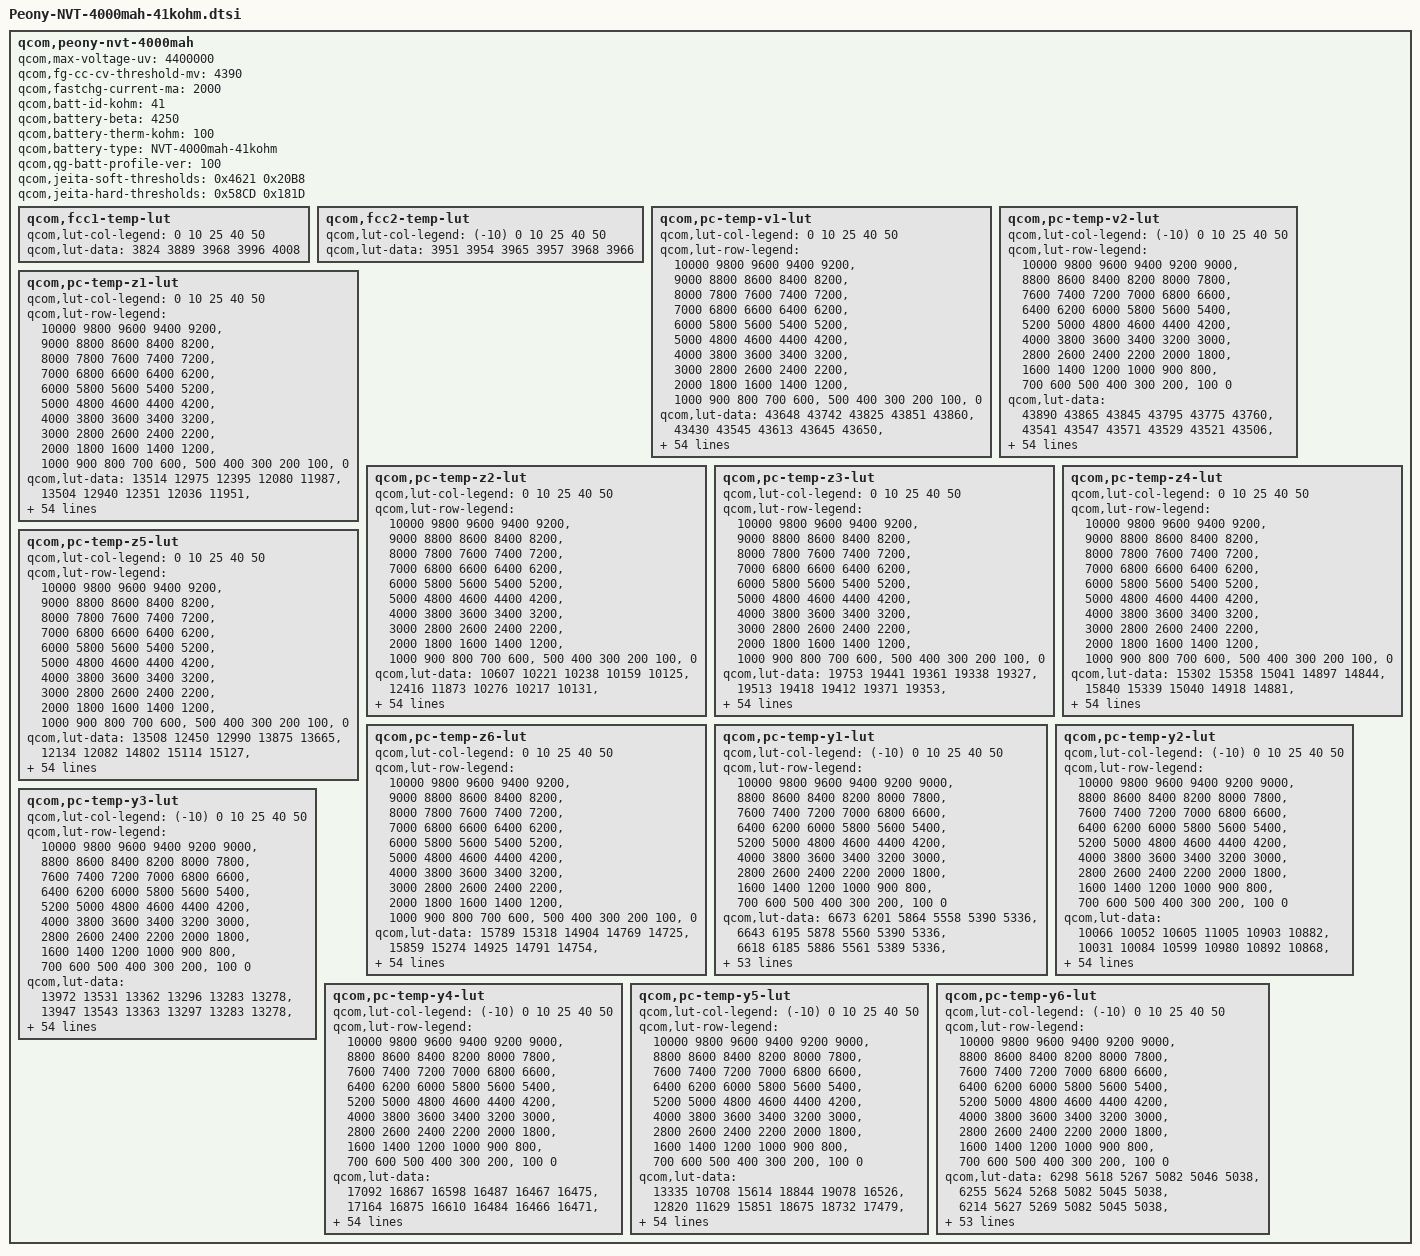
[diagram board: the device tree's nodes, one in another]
/* Copyright (c) 2018, The Linux Foundation. All rights reserved.
 * Copyright (C) 2021 XiaoMi, Inc.
 *
 * This program is free software; you can redistribute it and/or modify
 * it under the terms of the GNU General Public License version 2 and
 * only version 2 as published by the Free Software Foundation.
 *
 * This program is distributed in the hope that it will be useful,
 * but WITHOUT ANY WARRANTY; without even the implied warranty of
 * MERCHANTABILITY or FITNESS FOR A PARTICULAR PURPOSE.  See the
 * GNU General Public License for more details.
 */

qcom,peony-nvt-4000mah {
	/* Peony-NVT-4000mah-41kohm_Master_2018.12.27 */
	qcom,max-voltage-uv = <4400000>;
	qcom,fg-cc-cv-threshold-mv = <4390>;
	qcom,fastchg-current-ma = <2000>;
	qcom,batt-id-kohm = <41>;
	qcom,battery-beta = <4250>;
	qcom,battery-therm-kohm = <100>;
	qcom,battery-type =
		"NVT-4000mah-41kohm";
	qcom,qg-batt-profile-ver = <100>;

/*	qcom,jeita-fcc-ranges = <0   50   400000
				 51  100  1200000
				 101 150  1950000
				 151 450  2000000
				 451 550  1000000
				 551 600  0>;
	qcom,jeita-fv-ranges =  <0   50   4400000
				 51  100  4400000
				 101 150  4400000
				 151 450  4400000
				 451 550  4100000
				 551 600  4100000>;*/

	/* COOL = 15 DegC, WARM = 45 DegC */
	qcom,jeita-soft-thresholds = <0x4621 0x20B8>;
	/* COLD = 0 DegC, HOT = 55 DegC */
	qcom,jeita-hard-thresholds = <0x58CD 0x181D>;

	qcom,fcc1-temp-lut {
		qcom,lut-col-legend = <0 10 25 40 50>;
		qcom,lut-data = <3824 3889 3968 3996 4008>;
	};

	qcom,fcc2-temp-lut {
		qcom,lut-col-legend = <(-10) 0 10 25 40 50>;
		qcom,lut-data = <3951 3954 3965 3957 3968 3966>;
	};

	qcom,pc-temp-v1-lut {
		qcom,lut-col-legend = <0 10 25 40 50>;
		qcom,lut-row-legend = <10000 9800 9600 9400 9200>,
			<9000 8800 8600 8400 8200>,
			<8000 7800 7600 7400 7200>,
			<7000 6800 6600 6400 6200>,
			<6000 5800 5600 5400 5200>,
			<5000 4800 4600 4400 4200>,
			<4000 3800 3600 3400 3200>,
			<3000 2800 2600 2400 2200>,
			<2000 1800 1600 1400 1200>,
			<1000 900 800 700 600>,
			<500 400 300 200 100>,
			<0>;
		qcom,lut-data = <43648 43742 43825 43851 43860>,
			<43430 43545 43613 43645 43650>,
			<43175 43313 43394 43426 43434>,
			<42922 43056 43166 43204 43214>,
			<42688 42810 42932 42977 42989>,
			<42460 42577 42699 42747 42761>,
			<42234 42350 42467 42516 42529>,
			<42013 42126 42237 42285 42295>,
			<41796 41906 42012 42056 42067>,
			<41585 41689 41791 41828 41844>,
			<41380 41472 41571 41603 41623>,
			<41186 41262 41349 41380 41401>,
			<41012 41070 41133 41162 41181>,
			<40836 40898 40934 40956 40970>,
			<40617 40714 40743 40759 40764>,
			<40348 40482 40548 40565 40566>,
			<40111 40236 40338 40365 40374>,
			<39947 40044 40138 40169 40189>,
			<39809 39898 39972 39994 40015>,
			<39673 39758 39828 39844 39858>,
			<39544 39597 39653 39677 39688>,
			<39409 39426 39397 39446 39462>,
			<39245 39238 39142 39197 39214>,
			<39056 38997 38974 39015 39028>,
			<38882 38783 38845 38876 38890>,
			<38721 38677 38734 38755 38768>,
			<38581 38610 38637 38646 38650>,
			<38495 38547 38550 38547 38541>,
			<38436 38480 38466 38454 38444>,
			<38386 38416 38387 38364 38354>,
			<38338 38358 38315 38283 38275>,
			<38293 38304 38247 38210 38203>,
			<38252 38254 38185 38145 38138>,
			<38217 38208 38132 38085 38074>,
			<38184 38165 38086 38033 38015>,
			<38153 38126 38041 37981 37954>,
			<38125 38091 38000 37929 37893>,
			<38089 38051 37957 37873 37829>,
			<38031 37986 37893 37802 37750>,
			<37953 37896 37801 37710 37649>,
			<37859 37794 37698 37607 37540>,
			<37741 37678 37585 37497 37427>,
			<37605 37545 37457 37371 37300>,
			<37447 37386 37300 37212 37133>,
			<37307 37241 37157 37077 37009>,
			<37213 37149 37067 36988 36931>,
			<37188 37124 37040 36961 36907>,
			<37171 37108 37021 36944 36887>,
			<37150 37086 37005 36923 36864>,
			<37094 37035 36951 36858 36787>,
			<36870 36802 36698 36579 36478>,
			<36422 36361 36254 36140 36040>,
			<35849 35792 35681 35568 35464>,
			<35071 35015 34903 34790 34680>,
			<33834 33796 33683 33582 33461>,
			<30000 30000 30000 30000 30000>;
	};

	qcom,pc-temp-v2-lut {
		qcom,lut-col-legend = <(-10) 0 10 25 40 50>;
		qcom,lut-row-legend = <10000 9800 9600 9400 9200 9000>,
			<8800 8600 8400 8200 8000 7800>,
			<7600 7400 7200 7000 6800 6600>,
			<6400 6200 6000 5800 5600 5400>,
			<5200 5000 4800 4600 4400 4200>,
			<4000 3800 3600 3400 3200 3000>,
			<2800 2600 2400 2200 2000 1800>,
			<1600 1400 1200 1000 900 800>,
			<700 600 500 400 300 200>,
			<100 0>;
		qcom,lut-data = <43890 43865 43845 43795 43775 43760>,
			<43541 43547 43571 43529 43521 43506>,
			<43216 43250 43306 43271 43272 43258>,
			<42916 42977 43051 43024 43031 43019>,
			<42635 42727 42808 42786 42797 42788>,
			<42380 42484 42568 42552 42565 42559>,
			<42163 42238 42331 42319 42333 42327>,
			<41961 41994 42097 42087 42102 42096>,
			<41732 41755 41867 41859 41874 41868>,
			<41454 41516 41641 41635 41648 41642>,
			<41216 41296 41420 41413 41425 41419>,
			<41085 41112 41209 41197 41207 41201>,
			<40985 40944 41006 40985 40992 40986>,
			<40811 40760 40803 40780 40787 40780>,
			<40452 40558 40600 40579 40589 40580>,
			<40067 40336 40398 40383 40396 40388>,
			<39783 40060 40198 40184 40202 40199>,
			<39536 39750 39999 39987 40013 40016>,
			<39332 39509 39789 39805 39835 39841>,
			<39169 39336 39560 39644 39677 39679>,
			<39018 39178 39337 39476 39508 39507>,
			<38856 39005 39132 39260 39287 39287>,
			<38692 38830 38941 39014 39038 39041>,
			<38546 38675 38777 38818 38842 38847>,
			<38416 38544 38638 38672 38693 38698>,
			<38304 38422 38514 38549 38566 38571>,
			<38220 38297 38402 38436 38452 38455>,
			<38153 38173 38299 38336 38350 38352>,
			<38092 38083 38204 38244 38258 38259>,
			<38034 38026 38113 38157 38174 38174>,
			<37980 37980 38033 38079 38098 38097>,
			<37929 37935 37963 38007 38028 38026>,
			<37882 37894 37902 37941 37965 37961>,
			<37836 37855 37850 37878 37897 37890>,
			<37791 37817 37810 37821 37823 37809>,
			<37746 37779 37771 37764 37743 37720>,
			<37695 37736 37728 37698 37651 37617>,
			<37639 37689 37684 37623 37548 37499>,
			<37574 37631 37630 37546 37454 37397>,
			<37497 37560 37557 37469 37376 37316>,
			<37409 37475 37469 37387 37298 37237>,
			<37314 37373 37365 37287 37202 37140>,
			<37207 37248 37238 37168 37089 37029>,
			<37117 37109 37095 37042 36967 36909>,
			<37040 36973 36964 36929 36864 36808>,
			<36963 36894 36895 36874 36815 36762>,
			<36921 36867 36870 36857 36804 36750>,
			<36872 36839 36841 36840 36789 36734>,
			<36790 36798 36804 36805 36754 36698>,
			<36635 36702 36698 36715 36642 36567>,
			<36321 36445 36414 36411 36306 36202>,
			<35843 35979 35918 35919 35809 35696>,
			<35193 35342 35276 35289 35165 35044>,
			<34312 34447 34395 34448 34302 34179>,
			<33008 33113 33150 33163 33003 32856>,
			<27916 28151 28492 28147 28387 28206>;
	};

	qcom,pc-temp-z1-lut {
		qcom,lut-col-legend = <0 10 25 40 50>;
		qcom,lut-row-legend = <10000 9800 9600 9400 9200>,
			<9000 8800 8600 8400 8200>,
			<8000 7800 7600 7400 7200>,
			<7000 6800 6600 6400 6200>,
			<6000 5800 5600 5400 5200>,
			<5000 4800 4600 4400 4200>,
			<4000 3800 3600 3400 3200>,
			<3000 2800 2600 2400 2200>,
			<2000 1800 1600 1400 1200>,
			<1000 900 800 700 600>,
			<500 400 300 200 100>,
			<0>;
		qcom,lut-data = <13514 12975 12395 12080 11987>,
			<13504 12940 12351 12036 11951>,
			<13474 12903 12318 12016 11932>,
			<13451 12863 12299 12004 11922>,
			<13435 12837 12284 11995 11917>,
			<13421 12818 12269 11988 11914>,
			<13405 12804 12253 11982 11911>,
			<13383 12797 12240 11978 11909>,
			<13365 12787 12233 11977 11909>,
			<13355 12777 12228 11977 11911>,
			<13348 12756 12226 11977 11912>,
			<13338 12735 12225 11977 11912>,
			<13304 12727 12225 11977 11912>,
			<13264 12724 12223 11977 11912>,
			<13242 12721 12220 11977 11913>,
			<13225 12712 12218 11977 11914>,
			<13216 12700 12216 11977 11915>,
			<13216 12696 12214 11977 11915>,
			<13219 12697 12215 11977 11916>,
			<13220 12698 12220 11978 11918>,
			<13227 12701 12224 11980 11919>,
			<13235 12709 12227 11981 11919>,
			<13239 12712 12230 11983 11920>,
			<13247 12711 12233 11984 11921>,
			<13249 12709 12237 11986 11923>,
			<13243 12712 12241 11988 11926>,
			<13235 12720 12245 11991 11929>,
			<13236 12727 12250 11995 11932>,
			<13246 12734 12256 11999 11936>,
			<13258 12742 12264 12004 11939>,
			<13269 12746 12272 12009 11942>,
			<13282 12749 12280 12013 11946>,
			<13291 12751 12287 12018 11951>,
			<13292 12759 12292 12022 11955>,
			<13293 12769 12296 12027 11958>,
			<13302 12773 12300 12031 11962>,
			<13323 12773 12308 12036 11965>,
			<13334 12774 12317 12041 11969>,
			<13330 12783 12324 12045 11972>,
			<13325 12801 12330 12049 11976>,
			<13326 12809 12336 12053 11979>,
			<13339 12807 12345 12058 11982>,
			<13360 12807 12353 12062 11985>,
			<13402 12816 12356 12067 11987>,
			<13382 12824 12368 12073 11991>,
			<13373 12837 12368 12075 11992>,
			<13391 12852 12371 12074 11993>,
			<13366 12828 12375 12076 11993>,
			<13342 12811 12376 12079 11995>,
			<13389 12820 12377 12083 12000>,
			<13405 12840 12388 12091 12006>,
			<13367 12859 12401 12101 12013>,
			<13394 12893 12413 12110 12022>,
			<13459 12934 12445 12125 12038>,
			<13459 12934 12445 12125 12038>,
			<13459 12934 12445 12125 12038>;
	};

	qcom,pc-temp-z2-lut {
		qcom,lut-col-legend = <0 10 25 40 50>;
		qcom,lut-row-legend = <10000 9800 9600 9400 9200>,
			<9000 8800 8600 8400 8200>,
			<8000 7800 7600 7400 7200>,
			<7000 6800 6600 6400 6200>,
			<6000 5800 5600 5400 5200>,
			<5000 4800 4600 4400 4200>,
			<4000 3800 3600 3400 3200>,
			<3000 2800 2600 2400 2200>,
			<2000 1800 1600 1400 1200>,
			<1000 900 800 700 600>,
			<500 400 300 200 100>,
			<0>;
		qcom,lut-data = <10607 10221 10238 10159 10125>,
			<12416 11873 10276 10217 10131>,
			<10926 11524 10299 10241 10190>,
			<10092 10567 10303 10271 10230>,
			<10072 10184 10304 10319 10297>,
			<10058 10166 10301 10346 10343>,
			<10043 10155 10282 10323 10342>,
			<10026 10144 10263 10284 10334>,
			<10016 10134 10340 10263 10310>,
			<10017 10128 10540 10248 10195>,
			<10021 10124 10601 10238 10099>,
			<10029 10122 10425 10236 10084>,
			<10079 10151 10252 10235 10079>,
			<10135 10276 10325 10220 10087>,
			<10129 10356 10539 10169 10117>,
			<10069 10309 10637 10134 10141>,
			<10029 10233 10653 10125 10136>,
			<10049 10223 10661 10122 10123>,
			<10092 10244 10593 10127 10122>,
			<10123 10269 10394 10141 10143>,
			<10146 10289 10319 10166 10177>,
			<10165 10309 10381 10285 10263>,
			<10180 10317 10442 10446 10388>,
			<10193 10320 10422 10450 10412>,
			<10202 10321 10342 10304 10338>,
			<10209 10319 10307 10208 10278>,
			<10214 10310 10346 10259 10380>,
			<10216 10306 10392 10332 10561>,
			<10216 10314 10397 10348 10582>,
			<10217 10323 10394 10346 10417>,
			<10221 10326 10391 10336 10248>,
			<10229 10324 10380 10311 10149>,
			<10237 10324 10367 10279 10075>,
			<10246 10329 10368 10256 10064>,
			<10257 10338 10377 10236 10088>,
			<10268 10347 10388 10227 10123>,
			<10279 10356 10402 10264 10173>,
			<10290 10367 10422 10327 10233>,
			<10301 10383 10452 10352 10275>,
			<10312 10402 10502 10370 10311>,
			<10323 10413 10528 10375 10327>,
			<10335 10417 10526 10366 10315>,
			<10349 10423 10524 10354 10300>,
			<10376 10437 10524 10340 10368>,
			<10595 10559 10560 10348 10342>,
			<10636 10601 10546 10374 10268>,
			<10652 10600 10538 10381 10293>,
			<10652 10639 10532 10357 10285>,
			<10651 10656 10539 10407 10333>,
			<10650 10677 10588 10470 10433>,
			<10649 10721 10678 10351 10199>,
			<10507 10710 10539 10205 10054>,
			<10381 10609 10501 10155 10014>,
			<10163 10526 10449 10095 9962>,
			<10163 10526 10449 10095 9962>,
			<10163 10526 10449 10095 9962>;
	};

	qcom,pc-temp-z3-lut {
		qcom,lut-col-legend = <0 10 25 40 50>;
		qcom,lut-row-legend = <10000 9800 9600 9400 9200>,
			<9000 8800 8600 8400 8200>,
			<8000 7800 7600 7400 7200>,
			<7000 6800 6600 6400 6200>,
			<6000 5800 5600 5400 5200>,
			<5000 4800 4600 4400 4200>,
			<4000 3800 3600 3400 3200>,
			<3000 2800 2600 2400 2200>,
			<2000 1800 1600 1400 1200>,
			<1000 900 800 700 600>,
			<500 400 300 200 100>,
			<0>;
		qcom,lut-data = <19753 19441 19361 19338 19327>,
			<19513 19418 19412 19371 19353>,
			<19674 19465 19447 19391 19373>,
			<19769 19573 19463 19403 19388>,
			<19772 19615 19474 19412 19398>,
			<19774 19614 19477 19417 19406>,
			<19776 19611 19477 19417 19413>,
			<19778 19606 19477 19418 19418>,
			<19779 19597 19479 19417 19418>,
			<19770 19590 19486 19414 19407>,
			<19747 19585 19485 19411 19396>,
			<19737 19582 19467 19408 19393>,
			<19743 19579 19449 19406 19391>,
			<19749 19570 19447 19401 19389>,
			<19748 19563 19449 19390 19386>,
			<19733 19559 19450 19384 19382>,
			<19713 19552 19450 19383 19378>,
			<19680 19544 19449 19383 19372>,
			<19641 19529 19442 19382 19366>,
			<19628 19517 19424 19375 19360>,
			<19625 19523 19417 19370 19356>,
			<19624 19536 19429 19375 19359>,
			<19637 19545 19443 19382 19366>,
			<19674 19549 19438 19380 19365>,
			<19693 19552 19419 19361 19349>,
			<19693 19549 19411 19349 19336>,
			<19692 19540 19412 19357 19362>,
			<19690 19534 19413 19374 19410>,
			<19680 19532 19418 19389 19421>,
			<19668 19531 19432 19406 19415>,
			<19659 19531 19441 19415 19407>,
			<19651 19531 19446 19412 19398>,
			<19644 19532 19449 19406 19387>,
			<19638 19531 19447 19399 19377>,
			<19632 19530 19440 19390 19369>,
			<19625 19528 19433 19382 19363>,
			<19618 19523 19426 19377 19357>,
			<19612 19518 19419 19373 19353>,
			<19609 19515 19417 19370 19352>,
			<19606 19513 19416 19367 19353>,
			<19601 19509 19414 19365 19355>,
			<19594 19504 19412 19364 19356>,
			<19586 19497 19408 19364 19360>,
			<19576 19488 19401 19365 19371>,
			<19507 19459 19393 19362 19367>,
			<19492 19445 19379 19353 19353>,
			<19456 19440 19379 19347 19340>,
			<19387 19420 19378 19341 19335>,
			<19344 19418 19363 19335 19330>,
			<19340 19414 19357 19333 19317>,
			<19348 19404 19342 19355 19364>,
			<19350 19391 19375 19368 19363>,
			<19350 19356 19377 19368 19365>,
			<19346 19355 19356 19369 19368>,
			<19346 19355 19356 19369 19368>,
			<19346 19355 19356 19369 19368>;
	};

	qcom,pc-temp-z4-lut {
		qcom,lut-col-legend = <0 10 25 40 50>;
		qcom,lut-row-legend = <10000 9800 9600 9400 9200>,
			<9000 8800 8600 8400 8200>,
			<8000 7800 7600 7400 7200>,
			<7000 6800 6600 6400 6200>,
			<6000 5800 5600 5400 5200>,
			<5000 4800 4600 4400 4200>,
			<4000 3800 3600 3400 3200>,
			<3000 2800 2600 2400 2200>,
			<2000 1800 1600 1400 1200>,
			<1000 900 800 700 600>,
			<500 400 300 200 100>,
			<0>;
		qcom,lut-data = <15302 15358 15041 14897 14844>,
			<15840 15339 15040 14918 14881>,
			<15687 15281 15034 14916 14882>,
			<15524 15176 15004 14908 14880>,
			<15395 15086 14941 14876 14855>,
			<15274 15013 14892 14843 14823>,
			<15178 14951 14858 14819 14799>,
			<15099 14905 14826 14798 14777>,
			<15037 14868 14786 14777 14761>,
			<14997 14838 14744 14755 14750>,
			<14967 14815 14726 14740 14741>,
			<14930 14794 14729 14731 14733>,
			<14859 14769 14734 14724 14727>,
			<14796 14735 14724 14719 14720>,
			<14791 14718 14702 14714 14712>,
			<14810 14732 14689 14710 14706>,
			<14823 14754 14683 14704 14702>,
			<14822 14756 14678 14698 14699>,
			<14819 14740 14675 14692 14694>,
			<14814 14726 14674 14683 14688>,
			<14795 14726 14683 14678 14684>,
			<14777 14728 14740 14717 14716>,
			<14777 14736 14807 14785 14782>,
			<14782 14805 14835 14820 14816>,
			<14788 14874 14853 14843 14834>,
			<14816 14875 14859 14852 14843>,
			<14849 14855 14845 14834 14807>,
			<14854 14834 14823 14798 14738>,
			<14842 14816 14799 14767 14713>,
			<14828 14799 14770 14734 14707>,
			<14816 14782 14746 14712 14702>,
			<14805 14766 14727 14702 14698>,
			<14794 14752 14713 14695 14694>,
			<14782 14741 14708 14692 14692>,
			<14771 14733 14705 14691 14689>,
			<14762 14727 14703 14691 14688>,
			<14753 14723 14702 14691 14688>,
			<14747 14721 14702 14692 14690>,
			<14744 14724 14704 14696 14694>,
			<14742 14730 14714 14709 14708>,
			<14743 14732 14719 14718 14717>,
			<14746 14729 14714 14712 14709>,
			<14746 14727 14709 14706 14699>,
			<14741 14724 14711 14707 14699>,
			<14727 14707 14697 14696 14688>,
			<14723 14696 14689 14683 14674>,
			<14754 14693 14676 14678 14674>,
			<14820 14702 14665 14666 14661>,
			<14859 14694 14665 14649 14641>,
			<14859 14696 14670 14647 14647>,
			<14857 14720 14713 14666 14654>,
			<14876 14746 14687 14664 14665>,
			<14886 14791 14690 14670 14668>,
			<14906 14799 14717 14672 14668>,
			<14906 14799 14717 14672 14668>,
			<14906 14799 14717 14672 14668>;
	};

	qcom,pc-temp-z5-lut {
		qcom,lut-col-legend = <0 10 25 40 50>;
		qcom,lut-row-legend = <10000 9800 9600 9400 9200>,
			<9000 8800 8600 8400 8200>,
			<8000 7800 7600 7400 7200>,
			<7000 6800 6600 6400 6200>,
			<6000 5800 5600 5400 5200>,
			<5000 4800 4600 4400 4200>,
			<4000 3800 3600 3400 3200>,
			<3000 2800 2600 2400 2200>,
			<2000 1800 1600 1400 1200>,
			<1000 900 800 700 600>,
			<500 400 300 200 100>,
			<0>;
		qcom,lut-data = <13508 12450 12990 13875 13665>,
			<12134 12082 14802 15114 15127>,
			<13430 13007 16165 16443 16555>,
			<14441 15315 17013 17264 17696>,
			<14784 16710 17654 17793 18467>,
			<15038 17272 18201 18203 19260>,
			<15420 17657 18654 18527 20606>,
			<16041 17972 19130 18837 22088>,
			<16525 18325 20492 19322 22365>,
			<16636 18777 22908 20079 21588>,
			<16690 19533 23824 20837 20963>,
			<16837 20416 22825 21660 21231>,
			<18284 21474 21745 22383 21945>,
			<20205 23672 22429 22362 22739>,
			<21081 24858 24623 21561 23886>,
			<21639 24581 26179 21034 24612>,
			<21885 24177 27482 21798 24591>,
			<20700 23745 28649 23372 24522>,
			<18572 23278 28544 24840 24599>,
			<17991 23049 27140 26382 25375>,
			<18780 27323 27551 27621 26144>,
			<20351 37012 35040 28666 26532>,
			<27003 40569 42650 29518 26857>,
			<42245 40041 39597 28313 26080>,
			<49655 38984 27894 21208 20052>,
			<48549 36140 21350 16543 15466>,
			<46279 30074 19821 16722 18205>,
			<43242 26497 19028 17212 23588>,
			<38107 25549 19384 18379 25838>,
			<33658 25020 21180 22012 26745>,
			<31349 25165 23484 25582 27129>,
			<29652 26331 27374 28133 26690>,
			<28820 27862 31462 30111 25926>,
			<28412 29990 33409 30572 25820>,
			<28154 32309 34715 30684 26253>,
			<27956 33120 35172 30723 26561>,
			<27746 33165 34154 30556 26491>,
			<27653 33078 32428 30161 26290>,
			<28454 32946 31170 29323 25823>,
			<29670 32549 30110 26862 24421>,
			<29659 31867 28893 24423 23410>,
			<27838 29746 27132 22584 23255>,
			<27006 27620 25190 21583 23200>,
			<27092 25974 22997 21851 27267>,
			<24674 26399 23724 21719 26850>,
			<23176 25084 21655 20076 21643>,
			<19121 23922 22538 19129 18313>,
			<14576 19737 23560 18830 18574>,
			<12781 19878 20139 20281 21398>,
			<12768 19724 19165 20181 17768>,
			<13023 17694 15134 19809 26177>,
			<12778 15603 18346 20365 20774>,
			<12584 13515 18358 18698 19185>,
			<12247 13223 14735 17630 17978>,
			<12247 13223 14735 17630 17978>,
			<12247 13223 14735 17630 17978>;
	};

	qcom,pc-temp-z6-lut {
		qcom,lut-col-legend = <0 10 25 40 50>;
		qcom,lut-row-legend = <10000 9800 9600 9400 9200>,
			<9000 8800 8600 8400 8200>,
			<8000 7800 7600 7400 7200>,
			<7000 6800 6600 6400 6200>,
			<6000 5800 5600 5400 5200>,
			<5000 4800 4600 4400 4200>,
			<4000 3800 3600 3400 3200>,
			<3000 2800 2600 2400 2200>,
			<2000 1800 1600 1400 1200>,
			<1000 900 800 700 600>,
			<500 400 300 200 100>,
			<0>;
		qcom,lut-data = <15789 15318 14904 14769 14725>,
			<15859 15274 14925 14791 14754>,
			<15811 15252 14933 14796 14760>,
			<15756 15237 14923 14794 14761>,
			<15683 15215 14898 14785 14755>,
			<15594 15172 14876 14774 14748>,
			<15529 15125 14859 14764 14742>,
			<15482 15091 14842 14754 14736>,
			<15441 15062 14827 14744 14728>,
			<15404 15039 14812 14734 14717>,
			<15372 15022 14801 14725 14708>,
			<15339 15007 14792 14720 14703>,
			<15300 14988 14785 14715 14699>,
			<15265 14963 14777 14709 14694>,
			<15246 14950 14769 14702 14689>,
			<15234 14951 14764 14695 14684>,
			<15223 14952 14761 14692 14679>,
			<15206 14950 14758 14690 14675>,
			<15188 14936 14752 14685 14669>,
			<15177 14924 14744 14678 14663>,
			<15170 14926 14742 14674 14659>,
			<15166 14935 14775 14695 14677>,
			<15172 14948 14812 14729 14710>,
			<15194 14982 14817 14737 14719>,
			<15214 15013 14818 14739 14719>,
			<15230 15012 14818 14739 14719>,
			<15243 15001 14814 14736 14717>,
			<15244 14990 14806 14730 14714>,
			<15236 14983 14801 14726 14711>,
			<15226 14977 14796 14722 14706>,
			<15219 14971 14792 14718 14700>,
			<15212 14966 14789 14713 14694>,
			<15205 14962 14785 14708 14687>,
			<15200 14959 14782 14703 14681>,
			<15195 14957 14778 14698 14676>,
			<15190 14956 14775 14694 14672>,
			<15186 14954 14772 14691 14670>,
			<15185 14953 14770 14689 14668>,
			<15187 14956 14771 14690 14668>,
			<15190 14961 14776 14694 14675>,
			<15194 14963 14778 14698 14679>,
			<15197 14963 14776 14695 14678>,
			<15200 14963 14774 14693 14676>,
			<15202 14962 14773 14695 14681>,
			<15178 14949 14766 14689 14675>,
			<15168 14941 14756 14679 14662>,
			<15164 14936 14751 14674 14656>,
			<15158 14931 14746 14666 14647>,
			<15155 14928 14739 14656 14637>,
			<15155 14930 14739 14654 14632>,
			<15166 14941 14753 14676 14662>,
			<15185 14951 14762 14685 14669>,
			<15201 14961 14769 14690 14674>,
			<15228 14977 14775 14695 14680>,
			<15228 14977 14775 14695 14680>,
			<15228 14977 14775 14695 14680>;
	};

	qcom,pc-temp-y1-lut {
		qcom,lut-col-legend = <(-10) 0 10 25 40 50>;
		qcom,lut-row-legend = <10000 9800 9600 9400 9200 9000>,
			<8800 8600 8400 8200 8000 7800>,
			<7600 7400 7200 7000 6800 6600>,
			<6400 6200 6000 5800 5600 5400>,
			<5200 5000 4800 4600 4400 4200>,
			<4000 3800 3600 3400 3200 3000>,
			<2800 2600 2400 2200 2000 1800>,
			<1600 1400 1200 1000 900 800>,
			<700 600 500 400 300 200>,
			<100 0>;
		qcom,lut-data = <6673 6201 5864 5558 5390 5336>,
			<6643 6195 5878 5560 5390 5336>,
			<6618 6185 5886 5561 5389 5336>,
			<6599 6174 5888 5562 5388 5336>,
			<6587 6164 5888 5562 5387 5336>,
			<6583 6159 5886 5562 5385 5336>,
			<6589 6158 5879 5560 5384 5335>,
			<6601 6157 5870 5558 5382 5334>,
			<6603 6158 5868 5556 5381 5334>,
			<6598 6169 5873 5555 5380 5333>,
			<6593 6177 5878 5553 5380 5332>,
			<6589 6175 5878 5551 5379 5333>,
			<6582 6170 5877 5547 5378 5333>,
			<6576 6168 5876 5545 5378 5333>,
			<6573 6164 5872 5546 5377 5334>,
			<6572 6161 5869 5546 5377 5334>,
			<6584 6165 5872 5548 5378 5334>,
			<6607 6176 5877 5550 5381 5334>,
			<6614 6184 5879 5552 5381 5335>,
			<6604 6188 5885 5554 5381 5335>,
			<6596 6191 5888 5556 5381 5335>,
			<6608 6197 5883 5558 5381 5336>,
			<6630 6212 5872 5561 5382 5337>,
			<6638 6218 5870 5563 5384 5338>,
			<6632 6202 5883 5567 5386 5339>,
			<6621 6184 5896 5572 5388 5340>,
			<6600 6185 5900 5577 5391 5342>,
			<6561 6192 5901 5583 5394 5345>,
			<6543 6194 5901 5588 5397 5347>,
			<6558 6182 5897 5592 5401 5350>,
			<6576 6169 5894 5596 5405 5352>,
			<6577 6168 5896 5601 5408 5355>,
			<6576 6171 5901 5607 5411 5357>,
			<6574 6173 5908 5613 5414 5360>,
			<6568 6179 5924 5619 5418 5363>,
			<6564 6184 5938 5624 5421 5365>,
			<6563 6184 5935 5626 5423 5366>,
			<6557 6181 5921 5627 5424 5368>,
			<6552 6177 5915 5629 5426 5369>,
			<6555 6182 5923 5633 5429 5370>,
			<6561 6189 5936 5637 5431 5372>,
			<6560 6192 5944 5643 5433 5373>,
			<6544 6202 5950 5651 5435 5376>,
			<6539 6202 5954 5661 5438 5379>,
			<6546 6194 5954 5673 5444 5383>,
			<6589 6167 5934 5682 5449 5385>,
			<6603 6199 5959 5686 5448 5384>,
			<6623 6198 5977 5685 5447 5384>,
			<6571 6194 5963 5685 5446 5385>,
			<6571 6187 5942 5681 5447 5385>,
			<6597 6189 5945 5686 5449 5389>,
			<6618 6194 5950 5691 5458 5394>,
			<6658 6220 5991 5712 5467 5401>,
			<6720 6255 6005 5732 5477 5411>,
			<6720 6255 6005 5732 5477 5411>,
			<6720 6255 6005 5732 5477 5411>;
	};

	qcom,pc-temp-y2-lut {
		qcom,lut-col-legend = <(-10) 0 10 25 40 50>;
		qcom,lut-row-legend = <10000 9800 9600 9400 9200 9000>,
			<8800 8600 8400 8200 8000 7800>,
			<7600 7400 7200 7000 6800 6600>,
			<6400 6200 6000 5800 5600 5400>,
			<5200 5000 4800 4600 4400 4200>,
			<4000 3800 3600 3400 3200 3000>,
			<2800 2600 2400 2200 2000 1800>,
			<1600 1400 1200 1000 900 800>,
			<700 600 500 400 300 200>,
			<100 0>;
		qcom,lut-data = <10066 10052 10605 11005 10903 10882>,
			<10031 10084 10599 10980 10892 10868>,
			<10021 10123 10592 10953 10874 10853>,
			<10029 10160 10585 10927 10852 10837>,
			<10050 10188 10580 10902 10827 10820>,
			<10080 10200 10577 10880 10803 10805>,
			<10119 10195 10577 10855 10775 10782>,
			<10174 10186 10578 10833 10746 10752>,
			<10251 10190 10580 10829 10731 10734>,
			<10383 10245 10588 10833 10724 10718>,
			<10470 10318 10597 10838 10719 10709>,
			<10457 10393 10604 10842 10735 10707>,
			<10429 10473 10612 10847 10769 10706>,
			<10434 10524 10637 10856 10780 10706>,
			<10577 10555 10743 10874 10784 10706>,
			<10720 10586 10840 10902 10796 10710>,
			<10649 10624 10868 10950 10836 10732>,
			<10405 10670 10886 11023 10917 10780>,
			<10279 10738 10901 11090 11016 10851>,
			<9991 10876 10918 11163 11174 11007>,
			<9722 10989 10935 11210 11281 11121>,
			<9698 11007 10954 11184 11195 11089>,
			<9691 11011 10976 11118 11000 11007>,
			<9686 11002 11003 11094 10937 10969>,
			<9681 10953 11043 11113 10952 10957>,
			<9678 10905 11084 11142 10971 10952>,
			<9675 10901 11124 11171 10992 10962>,
			<9673 10901 11162 11205 11024 10988>,
			<9672 10881 11176 11240 11058 11017>,
			<9671 10407 11177 11281 11096 11049>,
			<9670 9858 11177 11319 11140 11089>,
			<9669 9758 11177 11345 11204 11154>,
			<9668 9724 11175 11369 11281 11248>,
			<9667 9711 11172 11377 11305 11291>,
			<9666 9701 11161 11374 11296 11242>,
			<9665 9690 11145 11368 11278 11175>,
			<9665 9684 11128 11349 11235 11143>,
			<9664 9679 11105 11299 11154 11093>,
			<9663 9676 11077 11269 11119 11053>,
			<9662 9672 11040 11266 11118 11013>,
			<9662 9670 10995 11263 11117 10978>,
			<9661 9667 10940 11247 11101 10974>,
			<9661 9664 10866 11201 11072 10977>,
			<9661 9662 10782 11161 11055 10936>,
			<9660 9661 10679 11118 10998 10823>,
			<9659 9659 10562 11056 10844 10722>,
			<9659 9659 10486 11080 10894 10726>,
			<9658 9658 10218 11044 10927 10753>,
			<9658 9658 10273 11046 10924 10753>,
			<9657 9657 10094 11060 10957 10758>,
			<9656 9657 9814 11030 10852 10699>,
			<9656 9656 9710 10952 10795 10625>,
			<9655 9655 9681 10879 10753 10558>,
			<9652 9654 9667 10848 10652 10484>,
			<9652 9654 9667 10848 10652 10484>,
			<9652 9654 9667 10848 10652 10484>;
	};

	qcom,pc-temp-y3-lut {
		qcom,lut-col-legend = <(-10) 0 10 25 40 50>;
		qcom,lut-row-legend = <10000 9800 9600 9400 9200 9000>,
			<8800 8600 8400 8200 8000 7800>,
			<7600 7400 7200 7000 6800 6600>,
			<6400 6200 6000 5800 5600 5400>,
			<5200 5000 4800 4600 4400 4200>,
			<4000 3800 3600 3400 3200 3000>,
			<2800 2600 2400 2200 2000 1800>,
			<1600 1400 1200 1000 900 800>,
			<700 600 500 400 300 200>,
			<100 0>;
		qcom,lut-data = <13972 13531 13362 13296 13283 13278>,
			<13947 13543 13363 13297 13283 13278>,
			<13899 13551 13364 13298 13283 13279>,
			<13844 13555 13365 13298 13284 13281>,
			<13797 13556 13367 13299 13284 13282>,
			<13774 13557 13368 13300 13285 13282>,
			<13772 13548 13370 13301 13285 13283>,
			<13771 13533 13372 13302 13286 13284>,
			<13758 13531 13372 13302 13287 13284>,
			<13671 13543 13371 13303 13288 13285>,
			<13586 13551 13371 13304 13289 13286>,
			<13551 13515 13372 13306 13290 13287>,
			<13526 13444 13374 13307 13292 13287>,
			<13521 13426 13373 13308 13294 13289>,
			<13524 13449 13363 13310 13296 13292>,
			<13526 13469 13356 13310 13298 13294>,
			<13500 13462 13357 13309 13299 13294>,
			<13442 13439 13360 13307 13299 13294>,
			<13422 13421 13360 13306 13299 13294>,
			<13429 13408 13354 13308 13298 13294>,
			<13436 13395 13346 13309 13296 13294>,
			<13438 13376 13340 13307 13292 13290>,
			<13439 13355 13334 13301 13286 13284>,
			<13439 13348 13330 13298 13284 13281>,
			<13424 13350 13328 13296 13283 13281>,
			<13408 13353 13326 13296 13282 13281>,
			<13410 13350 13323 13295 13282 13280>,
			<13421 13341 13320 13294 13282 13280>,
			<13433 13333 13318 13294 13281 13280>,
			<13444 13322 13318 13294 13281 13281>,
			<13457 13314 13317 13293 13281 13281>,
			<13473 13319 13316 13293 13282 13282>,
			<13493 13338 13315 13293 13284 13281>,
			<13515 13346 13314 13293 13284 13281>,
			<13537 13350 13315 13293 13284 13282>,
			<13561 13358 13316 13294 13284 13282>,
			<13586 13366 13317 13294 13283 13281>,
			<13613 13377 13319 13292 13281 13280>,
			<13643 13392 13320 13291 13281 13279>,
			<13676 13413 13321 13292 13283 13282>,
			<13711 13440 13321 13292 13286 13284>,
			<13744 13473 13322 13293 13286 13284>,
			<13775 13515 13323 13293 13286 13284>,
			<13818 13561 13325 13293 13285 13284>,
			<13876 13614 13329 13293 13284 13283>,
			<13948 13686 13333 13298 13288 13289>,
			<13921 13671 13333 13299 13293 13291>,
			<13968 13724 13332 13305 13297 13293>,
			<14032 13785 13345 13309 13298 13294>,
			<14107 13845 13355 13312 13297 13292>,
			<14186 13892 13369 13310 13292 13288>,
			<14313 13960 13396 13309 13294 13289>,
			<14492 14079 13438 13317 13299 13296>,
			<15046 14206 13510 13328 13306 13305>,
			<15046 14206 13510 13328 13306 13305>,
			<15046 14206 13510 13328 13306 13305>;
	};

	qcom,pc-temp-y4-lut {
		qcom,lut-col-legend = <(-10) 0 10 25 40 50>;
		qcom,lut-row-legend = <10000 9800 9600 9400 9200 9000>,
			<8800 8600 8400 8200 8000 7800>,
			<7600 7400 7200 7000 6800 6600>,
			<6400 6200 6000 5800 5600 5400>,
			<5200 5000 4800 4600 4400 4200>,
			<4000 3800 3600 3400 3200 3000>,
			<2800 2600 2400 2200 2000 1800>,
			<1600 1400 1200 1000 900 800>,
			<700 600 500 400 300 200>,
			<100 0>;
		qcom,lut-data = <17092 16867 16598 16487 16467 16475>,
			<17164 16875 16610 16484 16466 16471>,
			<17209 16883 16620 16483 16466 16469>,
			<17232 16890 16628 16482 16466 16467>,
			<17240 16897 16633 16483 16466 16465>,
			<17242 16903 16635 16485 16467 16465>,
			<17194 16909 16632 16487 16468 16465>,
			<17109 16915 16628 16490 16470 16467>,
			<17096 16910 16628 16494 16472 16468>,
			<17170 16866 16634 16500 16475 16470>,
			<17263 16832 16643 16506 16479 16472>,
			<17356 16935 16650 16511 16482 16475>,
			<17448 17141 16659 16517 16485 16478>,
			<17444 17195 16680 16525 16488 16481>,
			<17179 17128 16750 16541 16494 16485>,
			<16938 17035 16802 16561 16502 16489>,
			<16921 16940 16796 16581 16510 16496>,
			<16926 16838 16777 16602 16522 16506>,
			<16926 16795 16748 16613 16538 16520>,
			<16905 16784 16691 16619 16568 16545>,
			<16874 16774 16634 16622 16590 16563>,
			<16831 16757 16598 16594 16565 16545>,
			<16768 16735 16569 16522 16508 16500>,
			<16734 16707 16555 16488 16480 16478>,
			<16720 16662 16548 16479 16470 16469>,
			<16712 16618 16545 16474 16465 16464>,
			<16711 16587 16545 16476 16466 16465>,
			<16711 16562 16545 16480 16471 16468>,
			<16710 16555 16544 16486 16477 16473>,
			<16712 16586 16533 16491 16486 16479>,
			<16715 16624 16521 16497 16496 16488>,
			<16718 16634 16521 16504 16506 16499>,
			<16722 16634 16521 16511 16515 16512>,
			<16725 16637 16522 16514 16518 16516>,
			<16728 16646 16530 16514 16516 16514>,
			<16730 16657 16541 16514 16511 16511>,
			<16734 16666 16550 16510 16499 16500>,
			<16739 16675 16560 16498 16479 16478>,
			<16742 16680 16565 16492 16471 16469>,
			<16734 16679 16567 16493 16473 16474>,
			<16722 16676 16568 16493 16476 16479>,
			<16716 16672 16569 16495 16477 16480>,
			<16711 16662 16569 16497 16477 16479>,
			<16713 16650 16564 16496 16468 16466>,
			<16728 16640 16558 16492 16458 16451>,
			<16753 16645 16565 16501 16472 16476>,
			<16741 16646 16566 16502 16490 16505>,
			<16757 16658 16597 16519 16521 16539>,
			<16782 16682 16614 16549 16552 16566>,
			<16791 16712 16650 16573 16548 16549>,
			<16775 16714 16655 16524 16484 16480>,
			<16768 16700 16651 16514 16476 16476>,
			<16788 16707 16681 16537 16482 16480>,
			<17038 16743 16740 16595 16524 16519>,
			<17038 16743 16740 16595 16524 16519>,
			<17038 16743 16740 16595 16524 16519>;
	};

	qcom,pc-temp-y5-lut {
		qcom,lut-col-legend = <(-10) 0 10 25 40 50>;
		qcom,lut-row-legend = <10000 9800 9600 9400 9200 9000>,
			<8800 8600 8400 8200 8000 7800>,
			<7600 7400 7200 7000 6800 6600>,
			<6400 6200 6000 5800 5600 5400>,
			<5200 5000 4800 4600 4400 4200>,
			<4000 3800 3600 3400 3200 3000>,
			<2800 2600 2400 2200 2000 1800>,
			<1600 1400 1200 1000 900 800>,
			<700 600 500 400 300 200>,
			<100 0>;
		qcom,lut-data = <13335 10708 15614 18844 19078 16526>,
			<12820 11629 15851 18675 18732 17479>,
			<12582 12641 16093 18457 18362 18029>,
			<12573 13579 16325 18194 17984 18277>,
			<12747 14276 16532 17892 17616 18323>,
			<13056 14567 16700 17556 17273 18269>,
			<14399 14406 16902 17177 16949 17956>,
			<16399 14120 17110 16761 16628 17416>,
			<16585 14141 17090 16329 16305 17069>,
			<14327 14798 16616 15836 15944 16724>,
			<12534 15311 16045 15462 15671 16393>,
			<13117 14540 15517 15276 15665 16024>,
			<14818 13009 15017 15134 15842 15651>,
			<16991 13033 14880 14975 15893 15620>,
			<20807 17325 14922 14414 15720 16056>,
			<23543 21020 15047 13965 15501 16404>,
			<21410 20087 17078 14031 15343 15979>,
			<16279 17748 20989 14308 15198 15116>,
			<14414 17023 22184 14981 15218 14894>,
			<14872 17703 22107 18183 15851 15247>,
			<15399 18349 21921 21238 16737 15843>,
			<15450 18219 21354 21940 17912 17054>,
			<15476 17802 20349 22331 19352 18801>,
			<15396 17843 19831 22348 19727 19378>,
			<14198 21236 19779 21883 19368 19358>,
			<12940 24738 19840 21273 18822 19247>,
			<12838 23531 19784 20607 18063 18539>,
			<12845 19008 19654 19686 17030 17101>,
			<12847 15843 19687 19291 16538 16515>,
			<12818 14179 20869 19190 16344 16427>,
			<12784 13174 22035 19120 16250 16385>,
			<12810 13142 21569 19218 16553 16419>,
			<12945 13405 20122 19590 17471 16594>,
			<13127 13530 19353 19984 18395 16933>,
			<13442 13669 19156 20894 19457 18331>,
			<13788 13863 19064 21802 20213 19621>,
			<13959 13966 19099 21546 19900 19572>,
			<14065 14177 19274 20185 18851 19193>,
			<14143 14311 19351 19143 18424 19070>,
			<14235 14359 19070 18683 19143 19769>,
			<14309 14392 18609 18327 20144 20865>,
			<14102 14382 18120 18018 20819 22072>,
			<13308 14297 17621 17745 21369 23446>,
			<13055 14009 17717 17386 20315 22507>,
			<13060 13459 17912 16979 17891 19480>,
			<13162 13345 17028 16679 16592 17223>,
			<13305 13337 16381 16809 17582 16482>,
			<13650 13650 14789 17494 17543 15889>,
			<13738 13999 15518 17695 16721 15538>,
			<14162 14193 15265 18077 16521 15530>,
			<13909 14157 14813 19764 17450 16266>,
			<13884 13955 14430 19702 19339 16431>,
			<14059 14015 14666 21170 20961 19319>,
			<13477 14006 14994 23451 25092 25980>,
			<13477 14006 14994 23451 25092 25980>,
			<13477 14006 14994 23451 25092 25980>;
	};

	qcom,pc-temp-y6-lut {
		qcom,lut-col-legend = <(-10) 0 10 25 40 50>;
		qcom,lut-row-legend = <10000 9800 9600 9400 9200 9000>,
			<8800 8600 8400 8200 8000 7800>,
			<7600 7400 7200 7000 6800 6600>,
			<6400 6200 6000 5800 5600 5400>,
			<5200 5000 4800 4600 4400 4200>,
			<4000 3800 3600 3400 3200 3000>,
			<2800 2600 2400 2200 2000 1800>,
			<1600 1400 1200 1000 900 800>,
			<700 600 500 400 300 200>,
			<100 0>;
		qcom,lut-data = <6298 5618 5267 5082 5046 5038>,
			<6255 5624 5268 5082 5045 5038>,
			<6214 5627 5269 5082 5045 5038>,
			<6176 5627 5268 5082 5046 5039>,
			<6142 5625 5267 5082 5046 5039>,
			<6112 5622 5265 5083 5047 5040>,
			<6088 5614 5262 5084 5047 5040>,
			<6067 5602 5258 5085 5048 5041>,
			<6040 5594 5256 5087 5050 5042>,
			<6002 5587 5255 5089 5051 5043>,
			<5979 5583 5254 5091 5053 5044>,
			<5984 5588 5255 5093 5055 5046>,
			<5995 5598 5256 5095 5057 5047>,
			<5994 5600 5260 5099 5059 5049>,
			<5943 5598 5271 5104 5062 5052>,
			<5886 5594 5280 5110 5066 5055>,
			<5856 5573 5279 5115 5069 5057>,
			<5834 5532 5276 5119 5072 5060>,
			<5824 5511 5270 5122 5077 5064>,
			<5821 5504 5250 5125 5084 5070>,
			<5819 5498 5227 5127 5089 5075>,
			<5812 5489 5213 5117 5079 5068>,
			<5802 5479 5201 5092 5058 5050>,
			<5798 5476 5197 5081 5048 5041>,
			<5798 5477 5196 5078 5045 5038>,
			<5798 5478 5195 5077 5043 5037>,
			<5804 5480 5196 5077 5043 5037>,
			<5821 5481 5197 5079 5045 5038>,
			<5838 5483 5198 5080 5046 5040>,
			<5851 5497 5199 5083 5049 5042>,
			<5866 5519 5200 5085 5053 5045>,
			<5883 5538 5202 5088 5056 5049>,
			<5904 5557 5206 5091 5061 5053>,
			<5926 5578 5212 5093 5062 5054>,
			<5948 5601 5220 5095 5061 5054>,
			<5971 5626 5230 5096 5060 5053>,
			<5996 5654 5241 5095 5057 5050>,
			<6022 5685 5253 5092 5050 5043>,
			<6049 5717 5266 5090 5047 5040>,
			<6075 5751 5278 5091 5050 5043>,
			<6102 5787 5291 5093 5052 5046>,
			<6130 5828 5307 5095 5053 5047>,
			<6161 5874 5328 5097 5053 5047>,
			<6201 5923 5351 5099 5051 5044>,
			<6255 5978 5380 5102 5048 5040>,
			<6327 6047 5410 5112 5056 5051>,
			<6313 6043 5408 5112 5065 5061>,
			<6358 6092 5437 5121 5076 5073>,
			<6419 6150 5476 5132 5086 5081>,
			<6488 6212 5514 5141 5084 5075>,
			<6556 6258 5545 5127 5063 5053>,
			<6674 6320 5591 5127 5062 5053>,
			<6847 6427 5691 5147 5069 5060>,
			<7448 6554 5823 5179 5088 5080>,
			<7448 6554 5823 5179 5088 5080>,
			<7448 6554 5823 5179 5088 5080>;
	};
};
